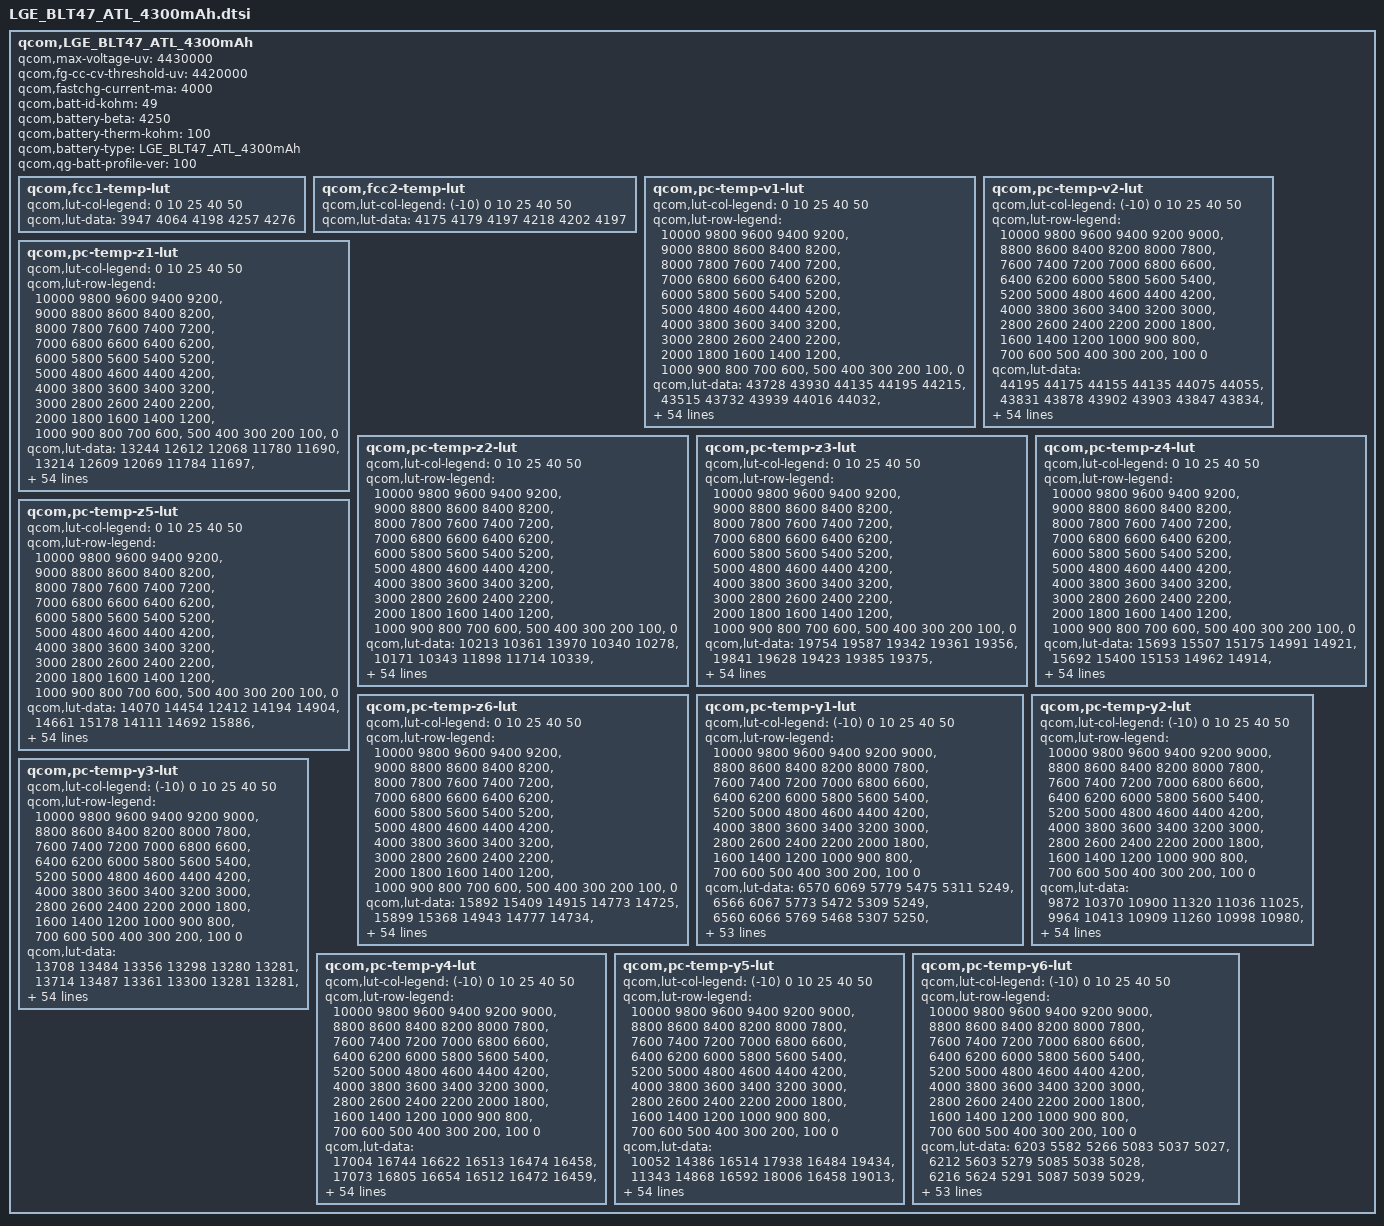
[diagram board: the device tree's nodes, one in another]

qcom,LGE_BLT47_ATL_4300mAh {
    /* 4359036_LGE_BLT47atl_4300mAh_averaged_MasterSlave_Jan21st2020 */
    qcom,max-voltage-uv = <4430000>;
    qcom,fg-cc-cv-threshold-uv = <4420000>;
    qcom,fastchg-current-ma = <4000>;
    qcom,batt-id-kohm = <49>;
    qcom,battery-beta = <4250>;
    qcom,battery-therm-kohm = <100>;
    qcom,battery-type = "LGE_BLT47_ATL_4300mAh";
    qcom,qg-batt-profile-ver = <100>;

	qcom,fcc1-temp-lut {
		qcom,lut-col-legend = <0 10 25 40 50>;
		qcom,lut-data = <3947 4064 4198 4257 4276>;
	};

	qcom,fcc2-temp-lut {
		qcom,lut-col-legend = <(-10) 0 10 25 40 50>;
		qcom,lut-data = <4175 4179 4197 4218 4202 4197>;
	};

	qcom,pc-temp-v1-lut {
		qcom,lut-col-legend = <0 10 25 40 50>;
		qcom,lut-row-legend = <10000 9800 9600 9400 9200>,
			<9000 8800 8600 8400 8200>,
			<8000 7800 7600 7400 7200>,
			<7000 6800 6600 6400 6200>,
			<6000 5800 5600 5400 5200>,
			<5000 4800 4600 4400 4200>,
			<4000 3800 3600 3400 3200>,
			<3000 2800 2600 2400 2200>,
			<2000 1800 1600 1400 1200>,
			<1000 900 800 700 600>,
			<500 400 300 200 100>,
			<0>;
		qcom,lut-data = <43728 43930 44135 44195 44215>,
			<43515 43732 43939 44016 44032>,
			<43296 43526 43741 43827 43843>,
			<43073 43312 43543 43631 43649>,
			<42848 43088 43333 43424 43449>,
			<42619 42859 43098 43205 43238>,
			<42389 42627 42851 42967 43014>,
			<42166 42393 42613 42726 42782>,
			<41946 42163 42382 42490 42547>,
			<41730 41936 42150 42253 42304>,
			<41519 41712 41912 42017 42066>,
			<41312 41495 41675 41781 41831>,
			<41112 41280 41447 41549 41600>,
			<40923 41075 41229 41325 41374>,
			<40738 40878 41018 41107 41151>,
			<40549 40688 40813 40895 40936>,
			<40351 40500 40615 40689 40727>,
			<40163 40315 40426 40490 40525>,
			<40000 40130 40253 40305 40335>,
			<39857 39950 40074 40128 40156>,
			<39702 39773 39856 39925 39959>,
			<39498 39577 39602 39667 39715>,
			<39268 39314 39371 39417 39470>,
			<39078 39051 39166 39229 39276>,
			<38922 38907 38990 39071 39113>,
			<38795 38829 38870 38938 38971>,
			<38709 38764 38782 38826 38846>,
			<38649 38693 38701 38725 38734>,
			<38597 38624 38614 38623 38628>,
			<38545 38555 38529 38522 38528>,
			<38496 38489 38449 38431 38436>,
			<38449 38424 38372 38350 38352>,
			<38401 38366 38302 38277 38274>,
			<38354 38311 38242 38209 38200>,
			<38309 38261 38189 38148 38132>,
			<38270 38216 38137 38086 38063>,
			<38227 38175 38091 38025 37992>,
			<38168 38121 38039 37961 37915>,
			<38090 38041 37966 37882 37828>,
			<37997 37943 37870 37786 37727>,
			<37887 37835 37763 37680 37617>,
			<37754 37707 37644 37563 37497>,
			<37597 37559 37507 37429 37362>,
			<37436 37385 37338 37261 37193>,
			<37325 37235 37185 37120 37059>,
			<37221 37140 37095 37034 36975>,
			<37183 37113 37069 37012 36951>,
			<37149 37090 37052 36996 36938>,
			<37119 37068 37029 36980 36919>,
			<37061 37023 36983 36931 36864>,
			<36868 36813 36778 36699 36608>,
			<36433 36377 36342 36262 36171>,
			<35861 35805 35776 35692 35602>,
			<35092 35026 35011 34921 34831>,
			<33842 33787 33817 33729 33634>,
			<30000 30000 30000 30000 30000>;
	};

	qcom,pc-temp-v2-lut {
		qcom,lut-col-legend = <(-10) 0 10 25 40 50>;
		qcom,lut-row-legend = <10000 9800 9600 9400 9200 9000>,
			<8800 8600 8400 8200 8000 7800>,
			<7600 7400 7200 7000 6800 6600>,
			<6400 6200 6000 5800 5600 5400>,
			<5200 5000 4800 4600 4400 4200>,
			<4000 3800 3600 3400 3200 3000>,
			<2800 2600 2400 2200 2000 1800>,
			<1600 1400 1200 1000 900 800>,
			<700 600 500 400 300 200>,
			<100 0>;
		qcom,lut-data = <44195 44175 44155 44135 44075 44055>,
			<43831 43878 43902 43903 43847 43834>,
			<43503 43601 43658 43675 43622 43613>,
			<43214 43344 43424 43452 43401 43395>,
			<42968 43112 43203 43234 43184 43180>,
			<42728 42882 42979 43013 42965 42962>,
			<42476 42637 42742 42781 42735 42733>,
			<42220 42389 42499 42542 42499 42499>,
			<41955 42142 42257 42304 42264 42265>,
			<41650 41898 42016 42065 42028 42030>,
			<41389 41655 41778 41830 41795 41798>,
			<41256 41407 41545 41597 41566 41569>,
			<41177 41155 41317 41369 41342 41343>,
			<41052 40949 41098 41146 41123 41124>,
			<40718 40813 40891 40929 40906 40910>,
			<40289 40683 40691 40719 40696 40702>,
			<39969 40483 40493 40516 40496 40501>,
			<39707 40194 40299 40319 40303 40306>,
			<39469 39903 40089 40125 40112 40114>,
			<39247 39647 39834 39936 39927 39931>,
			<39042 39403 39568 39741 39738 39746>,
			<38853 39177 39340 39511 39519 39530>,
			<38672 38969 39136 39243 39260 39273>,
			<38521 38773 38953 39020 39037 39050>,
			<38414 38569 38791 38862 38878 38893>,
			<38330 38374 38645 38730 38747 38764>,
			<38256 38246 38516 38606 38628 38644>,
			<38192 38166 38401 38493 38520 38534>,
			<38133 38104 38293 38389 38422 38432>,
			<38074 38049 38180 38291 38329 38338>,
			<38018 38003 38071 38201 38243 38250>,
			<37961 37958 37984 38120 38164 38169>,
			<37904 37913 37916 38045 38091 38095>,
			<37844 37868 37859 37975 38020 38020>,
			<37783 37820 37815 37907 37939 37931>,
			<37719 37770 37780 37841 37853 37830>,
			<37651 37715 37739 37768 37761 37726>,
			<37576 37653 37693 37684 37655 37616>,
			<37493 37582 37637 37596 37547 37507>,
			<37399 37498 37559 37510 37451 37406>,
			<37286 37393 37447 37423 37364 37315>,
			<37174 37274 37318 37320 37264 37213>,
			<37078 37133 37163 37185 37127 37075>,
			<36992 36982 37007 37051 36995 36943>,
			<36912 36861 36881 36925 36896 36847>,
			<36826 36774 36794 36878 36850 36801>,
			<36776 36746 36763 36860 36838 36790>,
			<36713 36718 36735 36840 36822 36774>,
			<36608 36675 36679 36806 36797 36749>,
			<36406 36572 36572 36727 36721 36659>,
			<36082 36313 36337 36468 36440 36361>,
			<35654 35839 35899 35986 35966 35883>,
			<35117 35215 35291 35364 35350 35261>,
			<34342 34371 34449 34517 34515 34426>,
			<33061 33125 33210 33298 33316 33199>,
			<29753 29780 29521 29521 29520 29519>;
	};

	qcom,pc-temp-z1-lut {
		qcom,lut-col-legend = <0 10 25 40 50>;
		qcom,lut-row-legend = <10000 9800 9600 9400 9200>,
			<9000 8800 8600 8400 8200>,
			<8000 7800 7600 7400 7200>,
			<7000 6800 6600 6400 6200>,
			<6000 5800 5600 5400 5200>,
			<5000 4800 4600 4400 4200>,
			<4000 3800 3600 3400 3200>,
			<3000 2800 2600 2400 2200>,
			<2000 1800 1600 1400 1200>,
			<1000 900 800 700 600>,
			<500 400 300 200 100>,
			<0>;
		qcom,lut-data = <13244 12612 12068 11780 11690>,
			<13214 12609 12069 11784 11697>,
			<13204 12605 12067 11785 11701>,
			<13197 12600 12064 11784 11702>,
			<13193 12597 12061 11783 11702>,
			<13193 12594 12056 11781 11702>,
			<13194 12589 12051 11778 11702>,
			<13192 12582 12047 11776 11702>,
			<13188 12578 12042 11777 11703>,
			<13183 12576 12040 11779 11706>,
			<13176 12574 12039 11779 11708>,
			<13163 12570 12039 11780 11709>,
			<13151 12563 12039 11780 11710>,
			<13144 12559 12041 11782 11712>,
			<13137 12562 12042 11784 11713>,
			<13133 12566 12043 11786 11715>,
			<13134 12566 12043 11789 11717>,
			<13136 12563 12043 11792 11720>,
			<13136 12559 12045 11795 11723>,
			<13133 12559 12048 11798 11727>,
			<13130 12559 12051 11800 11730>,
			<13129 12560 12054 11802 11732>,
			<13130 12562 12057 11804 11734>,
			<13130 12566 12062 11807 11737>,
			<13134 12569 12067 11811 11741>,
			<13139 12575 12072 11815 11745>,
			<13139 12580 12076 11819 11749>,
			<13134 12584 12081 11823 11753>,
			<13130 12586 12087 11828 11758>,
			<13134 12588 12093 11834 11764>,
			<13146 12591 12098 11839 11769>,
			<13153 12594 12103 11845 11773>,
			<13148 12596 12108 11850 11777>,
			<13141 12601 12112 11855 11782>,
			<13140 12605 12117 11860 11786>,
			<13151 12604 12121 11865 11791>,
			<13166 12602 12123 11869 11794>,
			<13174 12602 12125 11873 11797>,
			<13185 12611 12129 11877 11801>,
			<13194 12623 12135 11882 11805>,
			<13200 12627 12141 11887 11809>,
			<13203 12628 12150 11892 11814>,
			<13196 12633 12160 11897 11819>,
			<13182 12644 12168 11902 11823>,
			<13181 12652 12180 11912 11830>,
			<13178 12645 12186 11913 11832>,
			<13181 12649 12186 11915 11832>,
			<13182 12644 12183 11915 11834>,
			<13184 12641 12185 11918 11836>,
			<13200 12650 12194 11923 11840>,
			<13209 12664 12199 11931 11847>,
			<13204 12681 12220 11945 11859>,
			<13230 12690 12231 11961 11875>,
			<13265 12728 12262 11985 11899>,
			<13265 12728 12262 11985 11899>,
			<13265 12728 12262 11985 11899>;
	};

	qcom,pc-temp-z2-lut {
		qcom,lut-col-legend = <0 10 25 40 50>;
		qcom,lut-row-legend = <10000 9800 9600 9400 9200>,
			<9000 8800 8600 8400 8200>,
			<8000 7800 7600 7400 7200>,
			<7000 6800 6600 6400 6200>,
			<6000 5800 5600 5400 5200>,
			<5000 4800 4600 4400 4200>,
			<4000 3800 3600 3400 3200>,
			<3000 2800 2600 2400 2200>,
			<2000 1800 1600 1400 1200>,
			<1000 900 800 700 600>,
			<500 400 300 200 100>,
			<0>;
		qcom,lut-data = <10213 10361 13970 10340 10278>,
			<10171 10343 11898 11714 10339>,
			<10137 10324 11263 12338 10420>,
			<10107 10301 11128 12168 10624>,
			<10083 10262 11046 11754 10961>,
			<10062 10226 10759 11310 11066>,
			<10045 10201 10420 10724 11242>,
			<10034 10179 10344 10348 11438>,
			<10025 10167 10382 10307 11152>,
			<10020 10159 10408 10289 10393>,
			<10021 10155 10378 10305 10089>,
			<10025 10162 10336 10559 10714>,
			<10030 10190 10350 10810 11427>,
			<10043 10218 10488 10951 11530>,
			<10062 10236 10640 11181 11533>,
			<10082 10253 10785 11292 11556>,
			<10105 10269 11006 11382 11664>,
			<10129 10287 11136 11469 11793>,
			<10156 10300 11224 11416 11777>,
			<10187 10303 11281 11148 11445>,
			<10204 10303 11183 11009 11225>,
			<10207 10304 10851 10863 10933>,
			<10207 10302 10618 10699 10599>,
			<10207 10298 10512 10548 10496>,
			<10207 10297 10446 10347 10387>,
			<10207 10301 10440 10276 10338>,
			<10209 10308 10450 10328 10436>,
			<10216 10320 10464 10402 10568>,
			<10226 10338 10506 10460 10558>,
			<10236 10348 10560 10515 10414>,
			<10247 10351 10564 10532 10293>,
			<10257 10352 10525 10463 10213>,
			<10267 10354 10492 10385 10151>,
			<10276 10357 10487 10381 10150>,
			<10285 10360 10486 10400 10185>,
			<10295 10365 10491 10428 10231>,
			<10305 10373 10521 10495 10290>,
			<10317 10382 10560 10577 10358>,
			<10332 10401 10593 10624 10409>,
			<10348 10420 10627 10658 10458>,
			<10362 10428 10647 10681 10479>,
			<10376 10433 10657 10696 10466>,
			<10413 10443 10662 10704 10452>,
			<10441 10474 10665 10695 10469>,
			<9976 10684 10732 10595 10459>,
			<10033 10683 10727 10484 10417>,
			<10125 10681 10706 10495 10408>,
			<10159 10688 10677 10473 10418>,
			<10170 10827 10650 10531 10451>,
			<10219 11021 10707 10610 10578>,
			<10186 10810 10767 10607 10384>,
			<9896 10815 10751 10356 10191>,
			<9664 10745 10681 10287 10156>,
			<9537 10527 10844 10240 10505>,
			<9537 10527 10844 10240 10505>,
			<9537 10527 10844 10240 10505>;
	};

	qcom,pc-temp-z3-lut {
		qcom,lut-col-legend = <0 10 25 40 50>;
		qcom,lut-row-legend = <10000 9800 9600 9400 9200>,
			<9000 8800 8600 8400 8200>,
			<8000 7800 7600 7400 7200>,
			<7000 6800 6600 6400 6200>,
			<6000 5800 5600 5400 5200>,
			<5000 4800 4600 4400 4200>,
			<4000 3800 3600 3400 3200>,
			<3000 2800 2600 2400 2200>,
			<2000 1800 1600 1400 1200>,
			<1000 900 800 700 600>,
			<500 400 300 200 100>,
			<0>;
		qcom,lut-data = <19754 19587 19342 19361 19356>,
			<19841 19628 19423 19385 19375>,
			<19874 19658 19473 19407 19392>,
			<19894 19670 19517 19431 19407>,
			<19907 19677 19536 19453 19419>,
			<19918 19681 19534 19459 19430>,
			<19926 19684 19530 19459 19447>,
			<19928 19685 19535 19458 19461>,
			<19926 19686 19558 19450 19451>,
			<19923 19683 19570 19436 19418>,
			<19918 19677 19543 19430 19404>,
			<19911 19670 19500 19438 19422>,
			<19904 19657 19483 19447 19441>,
			<19895 19646 19483 19450 19441>,
			<19886 19640 19486 19450 19433>,
			<19879 19635 19490 19446 19425>,
			<19876 19628 19495 19440 19420>,
			<19872 19618 19493 19433 19413>,
			<19860 19611 19485 19420 19403>,
			<19836 19615 19478 19401 19387>,
			<19821 19628 19479 19394 19377>,
			<19835 19636 19486 19402 19378>,
			<19864 19638 19489 19410 19379>,
			<19876 19640 19477 19399 19370>,
			<19871 19638 19457 19369 19345>,
			<19862 19622 19442 19355 19332>,
			<19853 19608 19427 19353 19356>,
			<19841 19607 19421 19352 19391>,
			<19829 19608 19430 19367 19403>,
			<19819 19609 19448 19412 19409>,
			<19810 19616 19463 19432 19408>,
			<19803 19623 19477 19425 19399>,
			<19798 19624 19484 19415 19387>,
			<19795 19622 19479 19405 19378>,
			<19790 19618 19468 19395 19368>,
			<19785 19614 19460 19388 19363>,
			<19779 19608 19453 19384 19360>,
			<19771 19602 19448 19381 19359>,
			<19761 19595 19443 19378 19357>,
			<19749 19587 19438 19374 19356>,
			<19736 19579 19435 19372 19355>,
			<19720 19572 19433 19375 19356>,
			<19703 19562 19430 19377 19358>,
			<19666 19548 19422 19377 19364>,
			<19266 19492 19408 19367 19356>,
			<19263 19484 19396 19358 19347>,
			<19262 19477 19395 19354 19346>,
			<19262 19470 19387 19351 19335>,
			<19262 19415 19386 19340 19331>,
			<19261 19345 19379 19332 19325>,
			<19261 19429 19358 19337 19348>,
			<19264 19329 19370 19359 19361>,
			<19267 19310 19359 19362 19359>,
			<19271 19309 19326 19363 19311>,
			<19271 19309 19326 19363 19311>,
			<19271 19309 19326 19363 19311>;
	};

	qcom,pc-temp-z4-lut {
		qcom,lut-col-legend = <0 10 25 40 50>;
		qcom,lut-row-legend = <10000 9800 9600 9400 9200>,
			<9000 8800 8600 8400 8200>,
			<8000 7800 7600 7400 7200>,
			<7000 6800 6600 6400 6200>,
			<6000 5800 5600 5400 5200>,
			<5000 4800 4600 4400 4200>,
			<4000 3800 3600 3400 3200>,
			<3000 2800 2600 2400 2200>,
			<2000 1800 1600 1400 1200>,
			<1000 900 800 700 600>,
			<500 400 300 200 100>,
			<0>;
		qcom,lut-data = <15693 15507 15175 14991 14921>,
			<15692 15400 15153 14962 14914>,
			<15602 15304 15099 14930 14901>,
			<15454 15221 15000 14889 14877>,
			<15337 15147 14937 14847 14839>,
			<15250 15083 14919 14826 14804>,
			<15176 15028 14905 14817 14760>,
			<15118 14980 14877 14808 14724>,
			<15070 14940 14805 14795 14727>,
			<15030 14907 14757 14779 14747>,
			<14996 14878 14765 14761 14754>,
			<14965 14852 14785 14732 14715>,
			<14938 14827 14779 14705 14669>,
			<14913 14810 14756 14688 14658>,
			<14891 14799 14733 14667 14653>,
			<14872 14791 14714 14656 14649>,
			<14853 14790 14688 14649 14643>,
			<14839 14794 14677 14644 14639>,
			<14833 14797 14674 14647 14640>,
			<14830 14796 14673 14660 14650>,
			<14828 14791 14689 14678 14664>,
			<14844 14789 14749 14728 14711>,
			<14882 14856 14811 14787 14773>,
			<14915 14955 14876 14836 14818>,
			<14945 14978 14927 14882 14859>,
			<14968 14965 14932 14896 14874>,
			<14970 14947 14925 14887 14838>,
			<14955 14928 14913 14870 14782>,
			<14936 14904 14887 14834 14752>,
			<14920 14881 14847 14767 14728>,
			<14904 14857 14814 14731 14713>,
			<14887 14835 14782 14721 14707>,
			<14872 14822 14762 14715 14703>,
			<14858 14814 14758 14714 14701>,
			<14844 14807 14756 14713 14699>,
			<14831 14801 14755 14713 14699>,
			<14819 14796 14756 14716 14702>,
			<14811 14794 14758 14722 14708>,
			<14804 14796 14764 14731 14717>,
			<14797 14798 14777 14747 14730>,
			<14788 14794 14781 14754 14737>,
			<14777 14775 14766 14741 14728>,
			<14761 14760 14753 14730 14719>,
			<14754 14748 14748 14729 14719>,
			<15047 14716 14721 14716 14708>,
			<15041 14702 14708 14706 14696>,
			<15035 14696 14694 14694 14686>,
			<15029 14690 14678 14677 14674>,
			<15021 14739 14661 14662 14654>,
			<15011 14815 14663 14662 14650>,
			<15014 14728 14713 14693 14667>,
			<15034 14858 14714 14682 14664>,
			<15044 14885 14730 14682 14667>,
			<15061 14894 14769 14680 14717>,
			<15061 14894 14769 14680 14717>,
			<15061 14894 14769 14680 14717>;
	};

	qcom,pc-temp-z5-lut {
		qcom,lut-col-legend = <0 10 25 40 50>;
		qcom,lut-row-legend = <10000 9800 9600 9400 9200>,
			<9000 8800 8600 8400 8200>,
			<8000 7800 7600 7400 7200>,
			<7000 6800 6600 6400 6200>,
			<6000 5800 5600 5400 5200>,
			<5000 4800 4600 4400 4200>,
			<4000 3800 3600 3400 3200>,
			<3000 2800 2600 2400 2200>,
			<2000 1800 1600 1400 1200>,
			<1000 900 800 700 600>,
			<500 400 300 200 100>,
			<0>;
		qcom,lut-data = <14070 14454 12412 14194 14904>,
			<14661 15178 14111 14692 15886>,
			<15083 15763 14823 15312 16757>,
			<15454 16155 15428 16126 17446>,
			<15881 16420 15883 17073 18024>,
			<16416 16722 16414 17858 18886>,
			<16971 17195 17189 18602 21295>,
			<17450 17797 18576 18995 23565>,
			<17895 18426 22373 18868 22843>,
			<18309 19067 24684 18607 19981>,
			<18747 19775 22709 18821 18955>,
			<19314 20638 19647 22511 24484>,
			<19950 21696 19337 26234 30944>,
			<20572 22709 20998 27789 32495>,
			<21328 23736 22781 30010 33076>,
			<22678 24621 24910 31582 33878>,
			<26055 24821 28279 33871 35947>,
			<28985 24684 29871 35676 37900>,
			<28999 24551 30272 34371 37241>,
			<27953 26543 30707 30303 33176>,
			<27255 32852 33768 28823 30811>,
			<33213 36822 41376 32289 30411>,
			<44812 37470 44843 35987 29448>,
			<49324 37676 37877 32545 26100>,
			<46794 36619 27716 22229 18926>,
			<42730 31004 22723 16879 15370>,
			<39410 25952 19413 15483 16645>,
			<36157 25066 18065 14784 18441>,
			<33702 24635 18406 15985 19196>,
			<32530 24540 19276 19962 20816>,
			<31689 26198 20930 22774 21839>,
			<31380 29039 25218 24089 22221>,
			<31936 31444 28906 24988 22604>,
			<33075 33865 30395 25521 22930>,
			<34172 35673 31398 25896 23253>,
			<35301 36597 31633 26189 23567>,
			<36413 37256 31597 26498 24027>,
			<37404 37414 31494 26721 24446>,
			<38407 36522 30410 26010 23998>,
			<38946 35065 27808 23199 21726>,
			<37406 33721 26267 21573 20256>,
			<34674 32248 25809 21579 20083>,
			<34142 31155 25173 21653 20020>,
			<33483 30332 23328 21440 21055>,
			<11762 29299 24463 20989 20532>,
			<11540 28299 23361 19961 18894>,
			<11506 26403 23905 19711 19229>,
			<11487 24621 23275 20825 18528>,
			<11459 19646 25596 21313 21133>,
			<11476 14329 24390 20141 21298>,
			<11501 19331 16488 16506 20206>,
			<11469 12582 16284 17514 20564>,
			<11405 12034 14725 17278 19145>,
			<11335 11928 12811 16777 14796>,
			<11335 11928 12811 16777 14796>,
			<11335 11928 12811 16777 14796>;
	};

	qcom,pc-temp-z6-lut {
		qcom,lut-col-legend = <0 10 25 40 50>;
		qcom,lut-row-legend = <10000 9800 9600 9400 9200>,
			<9000 8800 8600 8400 8200>,
			<8000 7800 7600 7400 7200>,
			<7000 6800 6600 6400 6200>,
			<6000 5800 5600 5400 5200>,
			<5000 4800 4600 4400 4200>,
			<4000 3800 3600 3400 3200>,
			<3000 2800 2600 2400 2200>,
			<2000 1800 1600 1400 1200>,
			<1000 900 800 700 600>,
			<500 400 300 200 100>,
			<0>;
		qcom,lut-data = <15892 15409 14915 14773 14725>,
			<15899 15368 14943 14777 14734>,
			<15853 15327 14942 14777 14739>,
			<15774 15287 14921 14773 14736>,
			<15711 15247 14900 14766 14729>,
			<15662 15211 14890 14759 14721>,
			<15619 15181 14880 14754 14715>,
			<15583 15153 14867 14748 14708>,
			<15553 15129 14849 14738 14700>,
			<15525 15108 14832 14724 14692>,
			<15499 15088 14819 14715 14685>,
			<15476 15069 14807 14707 14679>,
			<15454 15049 14796 14701 14673>,
			<15432 15034 14787 14693 14667>,
			<15412 15024 14778 14686 14661>,
			<15395 15018 14771 14679 14655>,
			<15381 15013 14764 14673 14650>,
			<15369 15009 14759 14667 14645>,
			<15357 15006 14753 14662 14640>,
			<15345 15007 14749 14658 14636>,
			<15339 15011 14758 14659 14634>,
			<15355 15018 14787 14686 14655>,
			<15388 15052 14813 14716 14683>,
			<15409 15095 14833 14727 14694>,
			<15419 15104 14846 14733 14700>,
			<15425 15093 14846 14735 14702>,
			<15424 15080 14837 14730 14700>,
			<15413 15071 14828 14724 14695>,
			<15399 15063 14822 14719 14691>,
			<15389 15056 14816 14714 14685>,
			<15378 15051 14811 14709 14678>,
			<15370 15046 14807 14703 14671>,
			<15363 15043 14803 14696 14665>,
			<15357 15040 14798 14690 14659>,
			<15351 15037 14793 14684 14653>,
			<15345 15033 14789 14682 14651>,
			<15340 15030 14787 14682 14651>,
			<15338 15029 14785 14682 14652>,
			<15336 15031 14787 14684 14655>,
			<15334 15032 14792 14689 14660>,
			<15331 15031 14793 14692 14662>,
			<15327 15024 14788 14689 14660>,
			<15322 15019 14783 14686 14658>,
			<15310 15015 14779 14687 14662>,
			<15251 14986 14765 14677 14655>,
			<15249 14979 14755 14669 14645>,
			<15248 14974 14749 14662 14640>,
			<15246 14970 14739 14653 14630>,
			<15246 14966 14732 14641 14618>,
			<15248 14965 14731 14637 14613>,
			<15258 14979 14745 14655 14635>,
			<15279 14991 14756 14666 14645>,
			<15299 15002 14762 14671 14649>,
			<15328 15021 14770 14676 14653>,
			<15328 15021 14770 14676 14653>,
			<15328 15021 14770 14676 14653>;
	};

	qcom,pc-temp-y1-lut {
		qcom,lut-col-legend = <(-10) 0 10 25 40 50>;
		qcom,lut-row-legend = <10000 9800 9600 9400 9200 9000>,
			<8800 8600 8400 8200 8000 7800>,
			<7600 7400 7200 7000 6800 6600>,
			<6400 6200 6000 5800 5600 5400>,
			<5200 5000 4800 4600 4400 4200>,
			<4000 3800 3600 3400 3200 3000>,
			<2800 2600 2400 2200 2000 1800>,
			<1600 1400 1200 1000 900 800>,
			<700 600 500 400 300 200>,
			<100 0>;
		qcom,lut-data = <6570 6069 5779 5475 5311 5249>,
			<6566 6067 5773 5472 5309 5249>,
			<6560 6066 5769 5468 5307 5250>,
			<6554 6066 5766 5465 5304 5251>,
			<6549 6066 5765 5463 5302 5251>,
			<6546 6066 5764 5460 5301 5251>,
			<6553 6068 5765 5458 5301 5251>,
			<6566 6073 5767 5457 5301 5251>,
			<6571 6074 5768 5456 5300 5251>,
			<6566 6072 5767 5455 5300 5252>,
			<6561 6069 5766 5454 5300 5252>,
			<6557 6070 5765 5454 5300 5253>,
			<6556 6074 5761 5454 5300 5253>,
			<6556 6078 5760 5454 5300 5254>,
			<6558 6082 5764 5455 5301 5255>,
			<6561 6087 5769 5457 5303 5256>,
			<6565 6091 5770 5458 5304 5257>,
			<6573 6097 5771 5461 5305 5258>,
			<6578 6101 5771 5462 5307 5260>,
			<6574 6104 5770 5464 5308 5261>,
			<6568 6107 5770 5467 5310 5263>,
			<6568 6108 5771 5469 5312 5265>,
			<6576 6109 5773 5473 5315 5267>,
			<6582 6110 5776 5476 5317 5269>,
			<6592 6111 5780 5480 5320 5271>,
			<6610 6114 5786 5484 5322 5273>,
			<6613 6113 5788 5487 5324 5275>,
			<6591 6106 5788 5490 5327 5278>,
			<6569 6099 5788 5493 5331 5280>,
			<6568 6101 5791 5497 5334 5283>,
			<6568 6106 5795 5502 5337 5287>,
			<6569 6108 5797 5509 5341 5290>,
			<6570 6110 5800 5516 5345 5292>,
			<6571 6112 5804 5522 5348 5295>,
			<6577 6114 5804 5524 5352 5298>,
			<6595 6119 5802 5525 5355 5301>,
			<6608 6122 5802 5526 5358 5304>,
			<6605 6121 5807 5528 5361 5306>,
			<6601 6122 5813 5530 5363 5308>,
			<6600 6127 5818 5534 5365 5310>,
			<6599 6139 5824 5540 5367 5312>,
			<6598 6149 5828 5545 5370 5315>,
			<6602 6152 5827 5549 5374 5317>,
			<6612 6154 5825 5555 5377 5320>,
			<6627 6165 5830 5569 5380 5324>,
			<6665 6171 5835 5570 5384 5327>,
			<6712 6169 5838 5567 5385 5327>,
			<6712 6179 5845 5563 5384 5327>,
			<6720 6202 5851 5565 5384 5328>,
			<6750 6209 5858 5568 5385 5328>,
			<6781 6233 5876 5575 5387 5331>,
			<6824 6263 5895 5580 5395 5340>,
			<6890 6293 5933 5600 5407 5351>,
			<6985 6342 5966 5623 5423 5366>,
			<6985 6342 5966 5623 5423 5366>,
			<6985 6342 5966 5623 5423 5366>;
	};

	qcom,pc-temp-y2-lut {
		qcom,lut-col-legend = <(-10) 0 10 25 40 50>;
		qcom,lut-row-legend = <10000 9800 9600 9400 9200 9000>,
			<8800 8600 8400 8200 8000 7800>,
			<7600 7400 7200 7000 6800 6600>,
			<6400 6200 6000 5800 5600 5400>,
			<5200 5000 4800 4600 4400 4200>,
			<4000 3800 3600 3400 3200 3000>,
			<2800 2600 2400 2200 2000 1800>,
			<1600 1400 1200 1000 900 800>,
			<700 600 500 400 300 200>,
			<100 0>;
		qcom,lut-data = <9872 10370 10900 11320 11036 11025>,
			<9964 10413 10909 11260 10998 10980>,
			<10053 10459 10912 11201 10958 10933>,
			<10135 10504 10909 11147 10917 10887>,
			<10209 10542 10902 11099 10881 10845>,
			<10270 10569 10893 11059 10852 10811>,
			<10315 10586 10877 11025 10829 10780>,
			<10351 10599 10856 10996 10808 10752>,
			<10404 10601 10850 10986 10799 10742>,
			<10508 10587 10852 10983 10804 10738>,
			<10592 10572 10856 10983 10816 10736>,
			<10593 10601 10863 10990 10849 10733>,
			<10572 10694 10877 11007 10918 10728>,
			<10529 10745 10900 11030 10960 10730>,
			<10187 10715 10959 11068 10974 10808>,
			<9771 10671 11034 11118 10987 10904>,
			<9694 10705 11093 11182 11016 10931>,
			<9685 10854 11149 11263 11070 10936>,
			<9680 10951 11172 11332 11143 10951>,
			<9677 10957 11160 11394 11296 11095>,
			<9675 10960 11144 11438 11450 11284>,
			<9673 10957 11142 11417 11432 11295>,
			<9672 10925 11146 11323 11229 11166>,
			<9670 10865 11150 11272 11095 11076>,
			<9669 10573 11157 11288 11109 11079>,
			<9668 10032 11169 11319 11144 11090>,
			<9667 9794 11173 11346 11182 11108>,
			<9666 9738 11171 11374 11234 11155>,
			<9666 9708 11167 11399 11287 11206>,
			<9665 9696 11154 11425 11333 11249>,
			<9665 9689 11130 11450 11380 11290>,
			<9664 9684 11108 11460 11431 11306>,
			<9664 9679 11089 11466 11522 11310>,
			<9663 9674 11069 11470 11596 11313>,
			<9663 9671 11044 11470 11595 11323>,
			<9662 9668 11014 11465 11568 11350>,
			<9662 9666 10976 11456 11526 11359>,
			<9662 9664 10928 11417 11401 11321>,
			<9662 9662 10855 11371 11277 11260>,
			<9662 9661 10663 11347 11268 11203>,
			<9661 9661 10214 11328 11288 11140>,
			<9660 9660 9888 11301 11298 11109>,
			<9660 9660 9771 11256 11257 11110>,
			<9659 9659 9707 11194 11177 11110>,
			<9657 9659 9686 11092 11031 10974>,
			<9655 9658 9675 11005 10994 10836>,
			<9653 9657 9672 11008 10998 10805>,
			<9652 9657 9672 11060 11012 10851>,
			<9651 9656 9670 11031 11054 10932>,
			<9650 9655 9666 11025 11075 10937>,
			<9650 9653 9663 11010 10985 10837>,
			<9650 9651 9660 10929 10882 10781>,
			<9649 9650 9656 10848 10872 10704>,
			<9649 9649 9653 10784 10813 10625>,
			<9649 9649 9653 10784 10813 10625>,
			<9649 9649 9653 10784 10813 10625>;
	};

	qcom,pc-temp-y3-lut {
		qcom,lut-col-legend = <(-10) 0 10 25 40 50>;
		qcom,lut-row-legend = <10000 9800 9600 9400 9200 9000>,
			<8800 8600 8400 8200 8000 7800>,
			<7600 7400 7200 7000 6800 6600>,
			<6400 6200 6000 5800 5600 5400>,
			<5200 5000 4800 4600 4400 4200>,
			<4000 3800 3600 3400 3200 3000>,
			<2800 2600 2400 2200 2000 1800>,
			<1600 1400 1200 1000 900 800>,
			<700 600 500 400 300 200>,
			<100 0>;
		qcom,lut-data = <13708 13484 13356 13298 13280 13281>,
			<13714 13487 13361 13300 13281 13281>,
			<13714 13490 13366 13303 13283 13281>,
			<13709 13493 13371 13305 13284 13282>,
			<13700 13495 13375 13307 13286 13283>,
			<13689 13497 13378 13309 13287 13284>,
			<13676 13498 13380 13310 13289 13285>,
			<13658 13499 13382 13310 13290 13287>,
			<13635 13500 13384 13311 13291 13288>,
			<13597 13498 13385 13312 13292 13289>,
			<13562 13495 13386 13313 13293 13290>,
			<13547 13477 13386 13314 13296 13291>,
			<13537 13433 13382 13314 13300 13292>,
			<13534 13414 13378 13314 13302 13293>,
			<13556 13431 13368 13316 13302 13296>,
			<13584 13452 13358 13317 13302 13298>,
			<13581 13454 13359 13316 13302 13298>,
			<13552 13444 13367 13311 13303 13297>,
			<13533 13432 13371 13309 13303 13296>,
			<13535 13420 13365 13312 13302 13296>,
			<13539 13408 13355 13315 13301 13296>,
			<13539 13398 13350 13313 13297 13294>,
			<13531 13390 13346 13305 13290 13286>,
			<13525 13382 13343 13299 13285 13280>,
			<13530 13372 13341 13299 13283 13280>,
			<13547 13362 13338 13299 13282 13281>,
			<13567 13359 13337 13298 13281 13281>,
			<13591 13361 13335 13297 13282 13280>,
			<13619 13365 13334 13297 13283 13280>,
			<13651 13375 13333 13297 13283 13280>,
			<13687 13395 13331 13297 13283 13280>,
			<13726 13418 13330 13297 13283 13280>,
			<13766 13442 13329 13297 13285 13280>,
			<13807 13470 13328 13297 13287 13280>,
			<13851 13505 13329 13298 13287 13281>,
			<13897 13550 13332 13299 13286 13281>,
			<13944 13601 13336 13299 13285 13281>,
			<13990 13663 13340 13298 13284 13281>,
			<14036 13731 13345 13297 13282 13280>,
			<14078 13795 13349 13297 13283 13280>,
			<14114 13857 13354 13297 13285 13282>,
			<14156 13915 13361 13298 13286 13283>,
			<14210 13963 13378 13299 13283 13281>,
			<14292 14009 13405 13300 13281 13280>,
			<14484 14068 13438 13303 13284 13283>,
			<14893 14156 13491 13312 13290 13288>,
			<15267 14227 13517 13314 13293 13290>,
			<15624 14272 13510 13314 13296 13292>,
			<16114 14345 13540 13319 13300 13294>,
			<17330 14610 13600 13326 13300 13293>,
			<19314 15100 13677 13323 13293 13288>,
			<22676 15979 13808 13321 13291 13288>,
			<29167 17772 14118 13329 13297 13291>,
			<45868 21499 14672 13340 13304 13298>,
			<45868 21499 14672 13340 13304 13298>,
			<45868 21499 14672 13340 13304 13298>;
	};

	qcom,pc-temp-y4-lut {
		qcom,lut-col-legend = <(-10) 0 10 25 40 50>;
		qcom,lut-row-legend = <10000 9800 9600 9400 9200 9000>,
			<8800 8600 8400 8200 8000 7800>,
			<7600 7400 7200 7000 6800 6600>,
			<6400 6200 6000 5800 5600 5400>,
			<5200 5000 4800 4600 4400 4200>,
			<4000 3800 3600 3400 3200 3000>,
			<2800 2600 2400 2200 2000 1800>,
			<1600 1400 1200 1000 900 800>,
			<700 600 500 400 300 200>,
			<100 0>;
		qcom,lut-data = <17004 16744 16622 16513 16474 16458>,
			<17073 16805 16654 16512 16472 16459>,
			<17153 16892 16695 16513 16472 16460>,
			<17228 16982 16735 16514 16472 16461>,
			<17286 17056 16766 16516 16473 16461>,
			<17313 17091 16781 16518 16474 16462>,
			<17303 17086 16777 16520 16475 16463>,
			<17282 17072 16769 16523 16477 16464>,
			<17274 17064 16764 16526 16479 16465>,
			<17277 17059 16761 16531 16484 16468>,
			<17283 17057 16760 16537 16488 16471>,
			<17329 17080 16764 16545 16489 16476>,
			<17451 17154 16780 16555 16490 16481>,
			<17505 17206 16802 16566 16492 16485>,
			<17359 17231 16855 16576 16500 16488>,
			<17149 17246 16904 16588 16513 16491>,
			<17062 17224 16906 16611 16525 16498>,
			<17020 17109 16889 16645 16539 16512>,
			<16981 16997 16864 16660 16553 16528>,
			<16926 16929 16811 16660 16573 16545>,
			<16872 16872 16743 16657 16590 16560>,
			<16838 16817 16696 16633 16580 16553>,
			<16813 16764 16659 16560 16522 16507>,
			<16800 16719 16633 16516 16483 16474>,
			<16802 16681 16616 16511 16482 16472>,
			<16809 16649 16603 16509 16482 16470>,
			<16811 16642 16595 16509 16484 16471>,
			<16813 16659 16591 16516 16491 16478>,
			<16814 16677 16585 16523 16500 16488>,
			<16813 16682 16567 16530 16510 16497>,
			<16808 16684 16540 16538 16522 16506>,
			<16805 16687 16531 16546 16531 16516>,
			<16809 16695 16535 16556 16539 16528>,
			<16815 16707 16542 16563 16544 16536>,
			<16819 16719 16554 16562 16542 16533>,
			<16822 16732 16576 16558 16535 16520>,
			<16823 16742 16599 16551 16525 16507>,
			<16820 16751 16623 16529 16505 16494>,
			<16814 16759 16645 16512 16486 16483>,
			<16807 16759 16661 16512 16483 16481>,
			<16798 16752 16676 16514 16482 16481>,
			<16793 16740 16682 16517 16482 16479>,
			<16796 16719 16677 16521 16478 16471>,
			<16808 16696 16670 16522 16473 16459>,
			<16852 16693 16668 16520 16467 16453>,
			<16973 16696 16680 16535 16473 16463>,
			<17101 16715 16699 16541 16488 16488>,
			<17152 16724 16700 16538 16503 16510>,
			<17199 16737 16725 16562 16530 16539>,
			<17452 16808 16776 16579 16544 16541>,
			<17904 16913 16801 16560 16489 16480>,
			<19038 17127 16799 16541 16475 16464>,
			<22371 17881 16875 16565 16477 16468>,
			<37256 21253 17322 16611 16499 16489>,
			<37256 21253 17322 16611 16499 16489>,
			<37256 21253 17322 16611 16499 16489>;
	};

	qcom,pc-temp-y5-lut {
		qcom,lut-col-legend = <(-10) 0 10 25 40 50>;
		qcom,lut-row-legend = <10000 9800 9600 9400 9200 9000>,
			<8800 8600 8400 8200 8000 7800>,
			<7600 7400 7200 7000 6800 6600>,
			<6400 6200 6000 5800 5600 5400>,
			<5200 5000 4800 4600 4400 4200>,
			<4000 3800 3600 3400 3200 3000>,
			<2800 2600 2400 2200 2000 1800>,
			<1600 1400 1200 1000 900 800>,
			<700 600 500 400 300 200>,
			<100 0>;
		qcom,lut-data = <10052 14386 16514 17938 16484 19434>,
			<11343 14868 16592 18006 16458 19013>,
			<12971 15333 16708 17925 16399 18523>,
			<14645 15772 16833 17729 16313 18034>,
			<16074 16173 16940 17457 16206 17615>,
			<16964 16525 17000 17145 16083 17334>,
			<17341 16872 17019 16713 15948 17207>,
			<17587 17183 17032 16157 15788 17119>,
			<17573 17265 17014 15713 15575 16971>,
			<16496 17169 16834 15346 15201 16679>,
			<15402 16973 16566 14983 14924 16315>,
			<16096 16189 16249 14536 15193 15872>,
			<18526 14433 15802 14065 15927 15359>,
			<19945 13689 15372 13883 16204 15188>,
			<19974 16081 14890 13853 15583 15613>,
			<19615 19377 14535 13830 14798 16101>,
			<18672 20611 15412 13764 14494 15859>,
			<16352 21179 18731 13654 14307 14783>,
			<14987 21616 20863 13692 14250 14198>,
			<15002 22034 21240 16554 15165 15062>,
			<15030 22388 21481 19983 16643 16405>,
			<14882 22681 21832 20288 17537 16948>,
			<13665 22974 22311 19795 18227 17280>,
			<12519 23140 22574 19466 18541 17397>,
			<12230 20788 22513 19404 17670 17246>,
			<12047 15572 22400 19357 16163 16958>,
			<12009 13196 22462 19164 15694 16517>,
			<12056 12584 23157 18607 15609 15597>,
			<12128 12282 23734 18261 15574 14913>,
			<12256 12349 23605 18305 15603 14848>,
			<12539 12661 23129 18407 15701 14822>,
			<12769 12951 22357 18538 15916 14833>,
			<12917 13166 20185 18796 16894 15115>,
			<13072 13384 18200 19190 18007 15606>,
			<13244 13615 17924 20112 18604 16341>,
			<13488 13868 17892 21393 19059 17453>,
			<13736 14098 17888 21703 19199 18168>,
			<13985 14350 17974 20869 19026 18435>,
			<14203 14573 18076 19727 18824 18646>,
			<14183 14618 17771 18756 18807 18999>,
			<13579 14606 16532 17787 18876 19486>,
			<12937 14582 15432 17179 18869 19710>,
			<12708 14411 14791 16801 17582 19461>,
			<12545 14061 14463 16713 16464 19213>,
			<12352 13724 14503 17066 16845 19118>,
			<12066 13557 14277 16976 16853 18185>,
			<11738 13562 13929 16612 16620 16944>,
			<11594 13554 14072 16757 17096 16715>,
			<11397 13675 14027 16914 17754 16967>,
			<10723 13231 14168 18555 17656 16437>,
			<10090 12455 14375 19343 17569 17185>,
			<9545 11366 14244 19869 16937 18107>,
			<9180 10291 13541 20505 19778 18852>,
			<8915 9411 11551 21793 24230 24649>,
			<8915 9411 11551 21793 24230 24649>,
			<8915 9411 11551 21793 24230 24649>;
	};

	qcom,pc-temp-y6-lut {
		qcom,lut-col-legend = <(-10) 0 10 25 40 50>;
		qcom,lut-row-legend = <10000 9800 9600 9400 9200 9000>,
			<8800 8600 8400 8200 8000 7800>,
			<7600 7400 7200 7000 6800 6600>,
			<6400 6200 6000 5800 5600 5400>,
			<5200 5000 4800 4600 4400 4200>,
			<4000 3800 3600 3400 3200 3000>,
			<2800 2600 2400 2200 2000 1800>,
			<1600 1400 1200 1000 900 800>,
			<700 600 500 400 300 200>,
			<100 0>;
		qcom,lut-data = <6203 5582 5266 5083 5037 5027>,
			<6212 5603 5279 5085 5038 5028>,
			<6216 5624 5291 5087 5039 5029>,
			<6216 5643 5301 5089 5040 5030>,
			<6213 5657 5308 5090 5041 5031>,
			<6209 5663 5311 5092 5043 5032>,
			<6195 5661 5309 5093 5044 5033>,
			<6168 5655 5305 5094 5046 5035>,
			<6141 5649 5302 5095 5047 5036>,
			<6109 5644 5300 5097 5049 5038>,
			<6085 5639 5299 5099 5051 5040>,
			<6093 5634 5299 5101 5053 5041>,
			<6120 5630 5299 5104 5056 5043>,
			<6133 5629 5301 5107 5059 5046>,
			<6088 5647 5307 5111 5062 5048>,
			<6019 5669 5314 5116 5065 5051>,
			<5981 5666 5316 5121 5068 5054>,
			<5955 5634 5315 5127 5073 5057>,
			<5937 5602 5314 5131 5077 5060>,
			<5926 5582 5296 5133 5082 5065>,
			<5918 5564 5269 5134 5085 5069>,
			<5915 5551 5253 5126 5081 5066>,
			<5913 5541 5242 5099 5059 5047>,
			<5912 5533 5234 5084 5044 5033>,
			<5920 5523 5231 5083 5042 5033>,
			<5942 5514 5228 5082 5042 5033>,
			<5964 5512 5228 5082 5042 5033>,
			<5988 5529 5230 5084 5045 5035>,
			<6013 5555 5232 5087 5048 5037>,
			<6041 5581 5230 5090 5051 5040>,
			<6070 5613 5228 5093 5055 5043>,
			<6102 5648 5227 5096 5059 5046>,
			<6136 5686 5233 5100 5063 5050>,
			<6172 5729 5243 5103 5066 5053>,
			<6209 5777 5255 5104 5065 5052>,
			<6248 5832 5275 5105 5063 5050>,
			<6286 5889 5297 5104 5060 5046>,
			<6323 5951 5325 5099 5053 5042>,
			<6360 6014 5356 5093 5047 5039>,
			<6395 6071 5389 5094 5047 5039>,
			<6426 6123 5422 5097 5049 5040>,
			<6463 6169 5459 5100 5049 5041>,
			<6515 6206 5497 5103 5047 5037>,
			<6596 6241 5541 5108 5044 5033>,
			<6790 6293 5597 5113 5046 5035>,
			<7202 6374 5679 5128 5052 5041>,
			<7564 6440 5719 5130 5059 5051>,
			<7881 6484 5713 5127 5066 5058>,
			<8284 6555 5757 5139 5076 5068>,
			<9315 6810 5840 5150 5080 5068>,
			<10960 7262 5931 5143 5060 5047>,
			<13751 8036 6058 5140 5055 5044>,
			<19279 9606 6369 5160 5061 5049>,
			<34448 13209 6980 5189 5075 5062>,
			<34448 13209 6980 5189 5075 5062>,
			<34448 13209 6980 5189 5075 5062>;
	};

};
